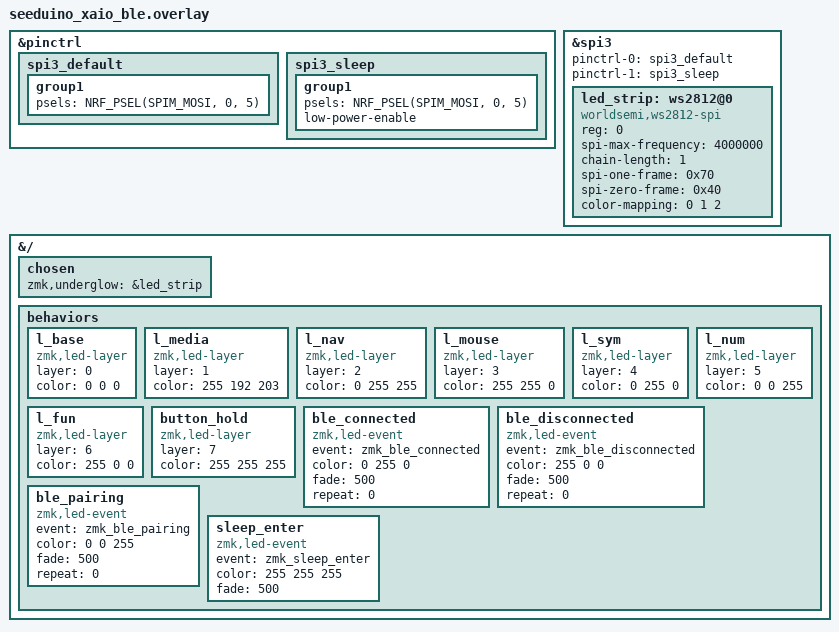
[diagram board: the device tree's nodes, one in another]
#include "m3d_q.dtsi"

/* ---------------------------
 * SPI3 接続 LED strip 定義 (WS2812 / SK6812)
 * --------------------------- */
&pinctrl {
    spi3_default: spi3_default {
        group1 {
            psels = <NRF_PSEL(SPIM_MOSI, 0, 5)>; /* D5 を MOSI に設定 */
        };
    };

    spi3_sleep: spi3_sleep {
        group1 {
            psels = <NRF_PSEL(SPIM_MOSI, 0, 5)>;
            low-power-enable;
        };
    };
};

&spi3 {
    status = "okay";
    pinctrl-0 = <&spi3_default>;
    pinctrl-1 = <&spi3_sleep>;
    pinctrl-names = "default", "sleep";

    /* LED strip ノードを作成 */
    led_strip: ws2812@0 {
        compatible = "worldsemi,ws2812-spi";
        reg = <0>;
        spi-max-frequency = <4000000>;
        chain-length = <1>;      /* LED 個数 */
        spi-one-frame = <0x70>;
        spi-zero-frame = <0x40>;
        color-mapping = <0 1 2>; /* RGB 順 */
    };
};

/* ---------------------------
 * ZMK にアンダーグロー LED と behaviors を選択
 * --------------------------- */
&{/} {
    chosen {
        zmk,underglow = &led_strip;
    };

    behaviors {
        l_base: l_base {
            compatible = "zmk,led-layer";
            layer = <0>;
            color = <0 0 0>;
        };
        l_media: l_media {
            compatible = "zmk,led-layer";
            layer = <1>;
            color = <255 192 203>;
        };
        l_nav: l_nav {
            compatible = "zmk,led-layer";
            layer = <2>;
            color = <0 255 255>;
        };
        l_mouse: l_mouse {
            compatible = "zmk,led-layer";
            layer = <3>;
            color = <255 255 0>;
        };
        l_sym: l_sym {
            compatible = "zmk,led-layer";
            layer = <4>;
            color = <0 255 0>;
        };
        l_num: l_num {
            compatible = "zmk,led-layer";
            layer = <5>;
            color = <0 0 255>;
        };
        l_fun: l_fun {
            compatible = "zmk,led-layer";
            layer = <6>;
            color = <255 0 0>;
        };
        button_hold: button_hold {
            compatible = "zmk,led-layer";
            layer = <7>;
            color = <255 255 255>;
        };

        ble_connected: ble_connected {
            compatible = "zmk,led-event";
            event = "zmk_ble_connected";
            color = <0 255 0>;
            fade = <500>;
            repeat = <0>;
        };
        ble_disconnected: ble_disconnected {
            compatible = "zmk,led-event";
            event = "zmk_ble_disconnected";
            color = <255 0 0>;
            fade = <500>;
            repeat = <0>;
        };
        ble_pairing: ble_pairing {
            compatible = "zmk,led-event";
            event = "zmk_ble_pairing";
            color = <0 0 255>;
            fade = <500>;
            repeat = <0>;
        };
        sleep_enter: sleep_enter {
            compatible = "zmk,led-event";
            event = "zmk_sleep_enter";
            color = <255 255 255>;
            fade = <500>;
        };
    };
};
